# R7FS3A17 register map
Vendor: Renesas; Series: S3; File version: 1.2
CPU: CM4 r0p1, little endian, MPU, FPU, VTOR, 4 interrupt priority bits
Registers are 8-bit, read-write, reset 0x0 unless marked. A register's access mark holds for its fields unless they carry their own. Offsets are from the block's base; [hi:lo] are bit positions; {n}, {i} and the like mark numbered series; 'fields as' and 'values as' point back to an identical list; <NAME> marks a mode.

## SYSTEM — System Control
Base 0x4001E000
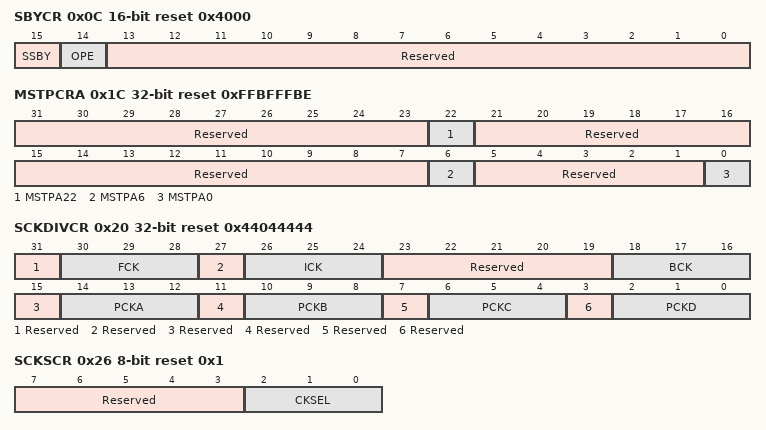
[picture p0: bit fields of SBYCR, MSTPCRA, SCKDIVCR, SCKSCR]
0x0C SBYCR 16-bit reset 0x4000 — Standby Control Register
  [15] SSBY — Software Standby
    0=Sleep mode; 1=Software Standby mode
  [14] OPE — Output Port Enable
    0=In software standby mode Address output pins, Data output pins, and other bus control signal output pins are set to the high-impedance state. In snooze mode, the status of the address bus and bus control signals are same as before entering software standby mode.; 1=In software standby mode Address output pins, Data output pins, and other bus control signal output pins retain the output state
  [13:0] Reserved — These bits are read as 00000000000000. The write value should be 00000000000000.
0x1C MSTPCRA 32-bit reset 0xFFBFFFBE — Module Stop Control Register A
  [31:23] Reserved — These bits are read as 111111111. The write value should be 111111111.
  [22] MSTPA22 — DMA Controller/Data Transfer Controller Module Stop
    0=Cancel the module-stop state; 1=Enter the module-stop state
  [21:7] Reserved — These bits are read as 111111111111111. The write value should be 111111111111111.
  [6] MSTPA6 — ECCRAM Module Stop
    values as MSTPA22
  [5:1] Reserved — These bits are read as 11111. The write value should be 11111.
  [0] MSTPA0 — RAM0 Module Stop
    values as MSTPA22
0x20 SCKDIVCR 32-bit reset 0x44044444 — System Clock Division Control Register
  [31] Reserved — This bit is read as 0. The write value should be 0.
  [30:28] FCK — Flash IF Clock (FCLK) Select
    0=/1; 1=/2; 2=/4; 3=/8; 4=/16; 5=/32; 6=/64; other=others (Setting prohibited)
  [27] Reserved — This bit is read as 0. The write value should be 0.
  [26:24] ICK — System Clock (ICLK) Select
    values as FCK
  [23:19] Reserved — These bits are read as 00000. The write value should be 00000.
  [18:16] BCK — External Bus Clock (BCLK) Select
    values as FCK
  [15] Reserved — This bit is read as 0. The write value should be 0.
  [14:12] PCKA — Peripheral Module Clock A (PCLKA) Select
    values as FCK
  [11] Reserved — This bit is read as 0. The write value should be 0.
  [10:8] PCKB — Peripheral Module Clock B (PCLKB) Select
    values as FCK
  [7] Reserved — This bit is read as 0. The write value should be 0.
  [6:4] PCKC — Peripheral Module Clock C (PCLKC) Select
    values as FCK
  [3] Reserved — This bit is read as 0. The write value should be 0.
  [2:0] PCKD — Peripheral Module Clock D (PCLKD) Select
    values as FCK
0x26 SCKSCR reset 0x1 — System Clock Source Control Register
  [7:3] Reserved — These bits are read as 00000. The write value should be 00000.
  [2:0] CKSEL — Clock Source Select Selecting the system clock source faster than 32MHz(system clock source > 32MHz ) is prohibit when SCKDIVCR.ICK[2:0] bits select the division-by-1 and MEMWAIT.MEMWAIT =0.
    0=HOCO; 1=MOCO; 2=LOCO; 3=Main clock oscillator; 4=Sub-clock oscillator; 5=PLL; other=others (Setting prohibited)
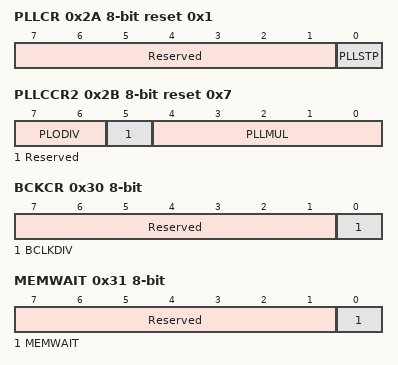
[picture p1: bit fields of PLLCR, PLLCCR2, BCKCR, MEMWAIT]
0x2A PLLCR reset 0x1 — PLL Control Register
  [7:1] Reserved — These bits are read as 0000000. The write value should be 0000000.
  [0] PLLSTP — PLL Stop Control
    0=PLL is operating; 1=PLL is stopped
0x2B PLLCCR2 reset 0x7 — PLL Clock Control Register2
  [7:6] PLODIV — PLL Output Frequency Division Ratio Select
    0=/1; 1=/2; 2=/4; 3=Setting prohibited
  [5] Reserved — This bit is read as 0. The write value should be 0.
  [4:0] PLLMUL — PLL Frequency Multiplication Factor Select
    15=Settings prohibited; other=others (x PLLMUL[4:0] +1)
0x30 BCKCR — External Bus Clock Control Register
  [7:1] Reserved — These bits are read as 0000000. The write value should be 0000000.
  [0] BCLKDIV — EBCLK Pin Output Select
    0=BCLK; 1=BCLK/2
0x31 MEMWAIT — Memory Wait Cycle Control Register
  [7:1] Reserved — These bits are read as 0000000. The write value should be 0000000.
  [0] MEMWAIT — Memory Wait Cycle Select Note: Writing 0 to the MEMWAIT is prohibited when SCKDIVCR.ICK selects division by 1 and SCKSCR.CKSEL[2:0] bits select the system clock source that is faster than 32 MHz (ICLK > 32 MHz).
    0=no wait; 1=wait
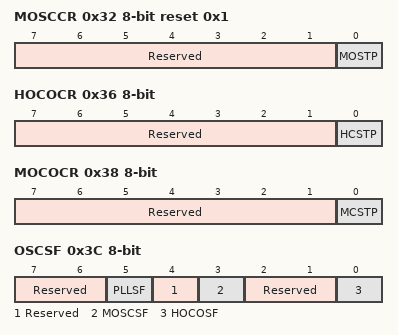
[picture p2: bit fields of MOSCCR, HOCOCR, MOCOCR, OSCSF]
0x32 MOSCCR reset 0x1 — Main Clock Oscillator Control Register
  [7:1] Reserved — These bits are read as 0000000. The write value should be 0000000.
  [0] MOSTP — Main Clock Oscillator Stop Note: MOMCR register must be set before setting MOSTP to 0.
    0=Main clock oscillator is operating; 1=Main clock oscillator is stopped
0x36 HOCOCR (reset mask 0xFE) — High-Speed On-Chip Oscillator Control Register
  [7:1] Reserved — These bits are read as 0000000. The write value should be 0000000.
  [0] HCSTP — HOCO Stop
    0=HOCO is operating; 1=HOCO is stopped
0x38 MOCOCR — Middle-Speed On-Chip Oscillator Control Register
  [7:1] Reserved — These bits are read as 0000000. The write value should be 0000000.
  [0] MCSTP — MOCO Stop
    0=MOCO is operating; 1=MOCO is stopped
0x3C OSCSF ro (reset mask 0xFE) — Oscillation Stabilization Flag Register
  [7:6] Reserved — These bits are read as 00.
  [5] PLLSF — PLL Clock Oscillation Stabilization Flag
    0=The PLL clock is stopped or oscillation of the PLL clock has not yet become stable; 1=Oscillation of the PLL clock is stable so the clock is available for use as the system clock
  [4] Reserved — This bit is read as 0.
  [3] MOSCSF — Main Clock Oscillation Stabilization Flag
    0=MOSTP = 1 (stopping the main clock oscillator) or oscillation of the main clock has not yet become stable; 1=Oscillation of the main clock is stable so the clock is available for use as the system clock
  [2:1] Reserved — These bits are read as 00.
  [0] HOCOSF — HOCO Clock Oscillation Stabilization Flag NOTE: The HOCOSF bit value after a reset is 1 when the OFS1.HOCOEN bit is 0. It is 0 when the OFS1.HOCOEN bit is 1.
    0=The HOCO clock is stopped or oscillation of the HOCO clock has not yet become stable; 1=Oscillation of the HOCO clock is stable so the clock is available for use as the system clock
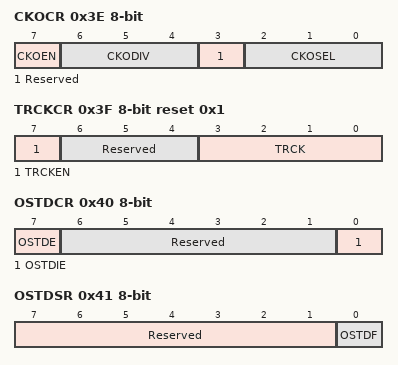
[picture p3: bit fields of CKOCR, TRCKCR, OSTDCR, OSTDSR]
0x3E CKOCR — Clock Out Control Register
  [7] CKOEN — Clock out enable
    0=Clock Out disable; 1=Clock Out enable
  [6:4] CKODIV — Clock out input frequency Division Select
    0=/1; 1=/2; 2=/4; 3=/8; 4=/16; 5=/32; 6=/64; 7=/128
  [3] Reserved — This bit is read as 0. The write value should be 0.
  [2:0] CKOSEL — Clock out source select
    0=HOCO; 1=MOCO; 2=LOCO; 3=MOSC; 4=SOSC; other=others (Setting prohibited)
0x3F TRCKCR reset 0x1 — Trace Clock Control Register
  [7] TRCKEN — Trace Clock operating enable
    0=Operation disabled; 1=Operation enabled
  [6:4] Reserved — These bits are read as 000. The write value should be 000.
  [3:0] TRCK — Trace Clock operating frequency select
    0=/1; 1=/2(value after reset); 2=/4; other=others (Setting prohibited)
0x40 OSTDCR — Oscillation Stop Detection Control Register
  [7] OSTDE — Oscillation Stop Detection Function Enable
    0=Oscillation stop detection function is disabled; 1=Oscillation stop detection function is enabled
  [6:1] Reserved — These bits are read as 000000. The write value should be 000000.
  [0] OSTDIE — Oscillation Stop Detection Interrupt Enable
    0=The oscillation stop detection interrupt is disabled. Oscillation stop detection is not notified to the POEG.; 1=The oscillation stop detection interrupt is enabled. Oscillation stop detection is notified to the POEG.
0x41 OSTDSR — Oscillation Stop Detection Status Register
  [7:1] Reserved — These bits are read as 0000000. The write value should be 0000000.
  [0] OSTDF write-0-clears read-modifies — Oscillation Stop Detection Flag
    0=The main clock oscillation stop has not been detected; 1=The main clock oscillation stop has been detected
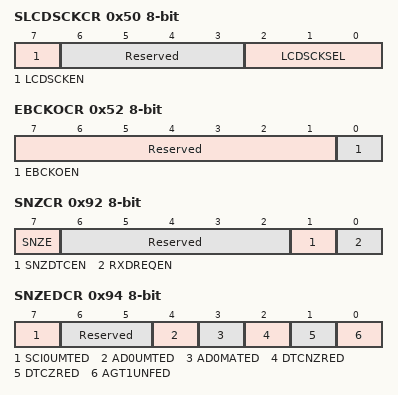
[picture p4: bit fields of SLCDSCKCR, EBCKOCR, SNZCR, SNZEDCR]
0x50 SLCDSCKCR — Segment LCD Source Clock Control Register
  [7] LCDSCKEN — LCD Source Clock Out Enable
    0=LCD source clock out disabled; 1=LCD source clock out enabled
  [6:3] Reserved — These bits are read as 0000. The write value should be 0000.
  [2:0] LCDSCKSEL — LCD Source Clock (LCDSRCCLK) Select
    0=LOCO; 1=SOSC; 2=MOSC; 4=HOCO; other=others (Settings other than above are prohibited.)
0x52 EBCKOCR — External Bus Clock Output Control Register
  [7:1] Reserved — These bits are read as 0000000. The write value should be 0000000.
  [0] EBCKOEN — EBCLK Pin Output Control
    0=BCLK pin output is disabled. (Fixed high); 1=BCLK pin output is enabled
0x61 MOCOUTCR — MOCO User Trimming Control Register
  [7:0] MOCOUTRM — MOCO User Trimming 1000_0000 : -128 1000_0001 : -127 1000_0010 : -126 . . . 1111_1111 : -1 0000_0000 : Center Code 0000_0001 : +1 . . . 0111_1101 : +125 0111_1110 : +126 0111_1111 : +127 These bits are added to original MOCO trimming bits
0x62 HOCOUTCR — HOCO User Trimming Control Register
  [7:0] HOCOUTRM — HOCO User Trimming 1000_0000 : -128 1000_0001 : -127 1000_0010 : -126 . . . 1111_1111 : -1 0000_0000 : Center Code 0000_0001 : +1 . . . 0111_1101 : +125 0111_1110 : +126 0111_1111 : +127 These bits are added to original HOCO trimming bits
0x92 SNZCR — Snooze Control Register
  [7] SNZE — Snooze Mode Enable
    0=Disable Snooze Mode; 1=Enable Snooze Mode
  [6:2] Reserved — These bits are read as 00000. The write value should be 00000.
  [1] SNZDTCEN — DTC Enable in Snooze Mode
    0=Disable DTC operation; 1=Enable DTC operation
  [0] RXDREQEN — RXD0 Snooze Request Enable NOTE: Do not set to 1 other than in asynchronous mode.
    0=Ignore RXD0 falling edge in Software Standby mode; 1=Accept RXD0 falling edge in Standby mode as a request to transit to Snooze mode
0x94 SNZEDCR — Snooze End Control Register
  [7] SCI0UMTED — SCI0 Address Mismatch Snooze End Enable
    0=Disable the Snooze End request; 1=Enable the Snooze End request
  [6:5] Reserved — These bits are read as 00. The write value should be 00.
  [4] AD0UMTED — ADC140 Compare Mismatch Snooze End Enable
    values as SCI0UMTED
  [3] AD0MATED — ADC140 Compare Match Snooze End Enable
    values as SCI0UMTED
  [2] DTCNZRED — Not Last DTC Transmission Completion Snooze End Enable
    values as SCI0UMTED
  [1] DTCZRED — Last DTC Transmission Completion Snooze End Enable
    values as SCI0UMTED
  [0] AGT1UNFED — AGT1 Underflow Snooze End Enable
    values as SCI0UMTED
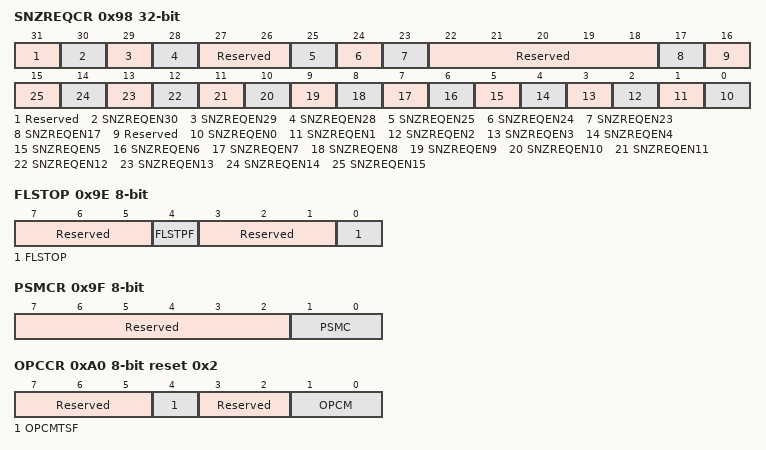
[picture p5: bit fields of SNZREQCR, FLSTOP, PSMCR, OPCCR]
0x98 SNZREQCR 32-bit — Snooze Request Control Register
  [31] Reserved — This bit is read as 0. The write value should be 0.
  [30] SNZREQEN30 — Snooze Request Enable 30 Enable AGT1 compare match B snooze request
    0=Disable snooze request; 1=Enable snooze request
  [29] SNZREQEN29 — Snooze Request Enable 29 Enable AGT1 compare match A snooze request
    0=Disable snooze request; 1=Enable snooze request
  [28] SNZREQEN28 — Snooze Request Enable 28 Enable AGT1 underflow snooze request
    0=Disable snooze request; 1=Enable snooze request
  [27:26] Reserved — These bits are read as 00. The write value should be 00.
  [25] SNZREQEN25 — Snooze Request Enable 25 Enable RTC period snooze request
    0=Disable snooze request; 1=Enable snooze request
  [24] SNZREQEN24 — Snooze Request Enable 24 Enable RTC alarm snooze request
    0=Disable snooze request; 1=Enable snooze request
  [23] SNZREQEN23 — Snooze Request Enable 23 Enable RTC alarm snooze request
    0=Disable snooze request; 1=Enable snooze request
  [22:18] Reserved — These bits are read as 00000. The write value should be 00000.
  [17] SNZREQEN17 — Snooze Request Enable 17 Enable KINT snooze request
    0=Disable snooze request; 1=Enable snooze request
  [16] Reserved — This bit is read as 0. The write value should be 0.
  [n] SNZREQEN{n} (n=0..15) — Snooze Request Enable {n} Enable IRQ{n} pin snooze request
    0=Disable snooze request; 1=Enable snooze request
0x9E FLSTOP — Flash Operation Control Register
  [7:5] Reserved — These bits are read as 000. The write value should be 000.
  [4] FLSTPF — Flash Memory Operation Status Flag
    0=Transition completed; 1=During transition (from the flash-stop-status to flash-operating-status or vice versa)
  [3:1] Reserved — These bits are read as 000. The write value should be 000.
  [0] FLSTOP — Selecting ON/OFF of the Flash Memory Operation
    0=Code flash and data flash memory operates; 1=Code flash and data flash memory stops
0x9F PSMCR — Power Save Memory Control Register
  [7:2] Reserved — These bits are read as 000000. The write value should be 000000.
  [1:0] PSMC — Power save memory control.
    0=All RAM is on Software Standby mode; 1=48KB RAM is on in Software Standby mode; other=others (Setting prohibited.)
0xA0 OPCCR reset 0x2 — Operating Power Control Register
  [7:5] Reserved — These bits are read as 000. The write value should be 000.
  [4] OPCMTSF — Operating Power Control Mode Transition Status Flag
    0=Transition completed; 1=During transition
  [3:2] Reserved — These bits are read as 00. The write value should be 00.
  [1:0] OPCM — Operating Power Control Mode Select
    0=High-speed mode; 1=Middle-speed mode; 2=Low-voltage mode; 3=Low-speed mode
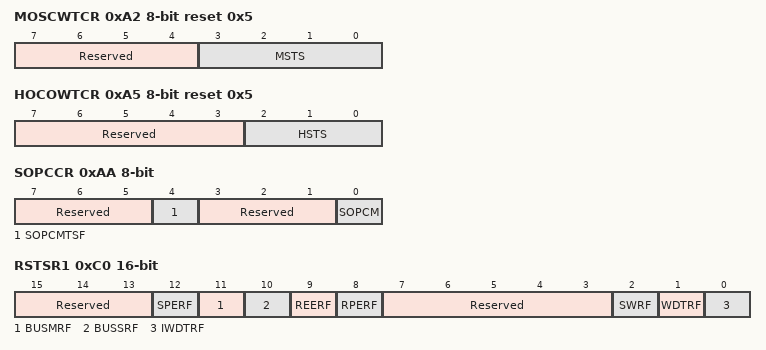
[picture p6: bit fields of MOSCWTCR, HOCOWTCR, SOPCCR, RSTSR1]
0xA2 MOSCWTCR reset 0x5 — Main Clock Oscillator Wait Control Register
  [7:4] Reserved — These bits are read as 0000. The write value should be 0000.
  [3:0] MSTS — Main clock oscillator wait time setting
    0=Wait time = 2 cycles (0.25 us); 1=Wait time = 1024 cycles (128 us); 2=Wait time = 2048 cycles (256 us); 3=Wait time = 4096 cycles (512 us); 4=Wait time = 8192 cycles (1024 us); 5=Wait time = 16384 cycles (2048 us) (value after reset); 6=Wait time = 32768 cycles (4096 us); 7=Wait time = 65536 cycles (8192 us); 8=Wait time = 131072 cycles (16384 us); 9=Wait time = 262144 cycles (32768 us); other=others (Setting prohibited)
0xA5 HOCOWTCR reset 0x5 — High-Speed On-Chip Oscillator Wait Control Register
  [7:3] Reserved — These bits are read as 00000. The write value should be 00000.
  [2:0] HSTS — HOCO wait time setting
    5=If HOCO frequency is other than 64MHz, should set the value to 101b; 6=If HOCO frequency = 64MHz, should set the value to 110b; other=others (Setting prohibited)
0xAA SOPCCR — Sub Operating Power Control Register
  [7:5] Reserved — These bits are read as 000. The write value should be 000.
  [4] SOPCMTSF ro — Sub Operating Power Control Mode Transition Status Flag
    0=Transition completed; 1=During transition
  [3:1] Reserved — These bits are read as 000. The write value should be 000.
  [0] SOPCM — Sub Operating Power Control Mode Select
    0=Other than Subosc-speed mode; 1=Subosc-speed mode
0xC0 RSTSR1 16-bit (reset mask 0xE0F8) — Reset Status Register 1
  [15:13] Reserved — These bits are read as 000. The write value should be 000.
  [12] SPERF write-0-clears read-modifies — SP Error Reset Detect Flag Note: Only 0 can be written to clear the flag. The reset flag must be written as 0 after the reset flag is read as 1.
    0=SP error reset not detected; 1=SP error reset detected
  [11] BUSMRF write-0-clears read-modifies — Bus Master MPU Reset Detect Flag Note: Only 0 can be written to clear the flag. The reset flag must be written as 0 after the reset flag is read as 1.
    0=Bus Master MPU reset not detected; 1=Bus Master MPU reset detected
  [10] BUSSRF write-0-clears read-modifies — Bus Slave MPU Reset Detect Flag Note: Only 0 can be written to clear the flag. The reset flag must be written as 0 after the reset flag is read as 1.
    0=Bus Slave MPU reset not detected; 1=Bus Slave MPU reset detected
  [9] REERF write-0-clears read-modifies — RAM ECC Error Reset Detect Flag Note: Only 0 can be written to clear the flag. The reset flag must be written as 0 after the reset flag is read as 1.
    0=RAM ECC error reset not detected; 1=RAM ECC error reset detected
  [8] RPERF write-0-clears read-modifies — RAM Parity Error Reset Detect Flag Note: Only 0 can be written to clear the flag. The reset flag must be written as 0 after the reset flag is read as 1.
    0=RAM parity error reset not detected; 1=RAM parity error reset detected
  [7:3] Reserved — These bits are read as 00000. The write value should be 00000.
  [2] SWRF write-0-clears read-modifies — Software Reset Detect Flag Note: Only 0 can be written to clear the flag. The reset flag must be written as 0 after the reset flag is read as 1.
    0=Software reset not detected; 1=Software reset detected
  [1] WDTRF write-0-clears read-modifies — Watchdog Timer Reset Detect Flag Note: Only 0 can be written to clear the flag. The reset flag must be written as 0 after the reset flag is read as 1.
    0=Watchdog timer reset not detected; 1=Watchdog timer reset detected
  [0] IWDTRF write-0-clears read-modifies — Independent Watchdog Timer Reset Detect Flag Note: Only 0 can be written to clear the flag. The reset flag must be written as 0 after the reset flag is read as 1.
    0=Independent watchdog timer reset not detected; 1=Independent watchdog timer reset detected
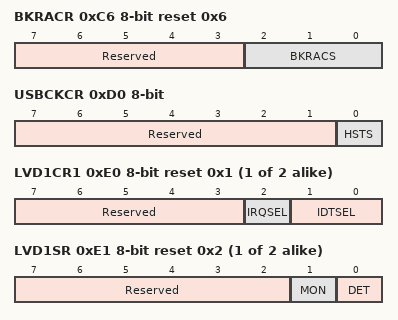
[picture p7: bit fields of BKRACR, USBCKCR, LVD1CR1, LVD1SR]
0xC6 BKRACR reset 0x6 — Backup Register Access Control Register
  [7:3] Reserved — These bits are read as 00000. The write value should be 00000.
  [2:0] BKRACS — Backup Register Access Control Register
    0=Access control disable. When System clock source is SOSC or LOCO.; 6=Access control enable. System clock source is other than SOSC or LOCO.; other=others (Setting prohibited)
0xD0 USBCKCR — USB Clock Control register
  [7:1] Reserved — These bits are read as 0000000. The write value should be 0000000.
  [0] HSTS — USB Clock Source Select
    0=PLL(Value after reset); 1=HOCO
{0xDE+2i} LVD{i}CR1 (i=1..2) reset 0x1 — Voltage Monitor {i} Circuit Control Register 1
  [7:3] Reserved — These bits are read as 00000. The write value should be 00000.
  [2] IRQSEL — Voltage Monitor Interrupt Type Select
    0=Non-maskable interrupt; 1=Maskable interrupt
  [1:0] IDTSEL — Voltage Monitor Interrupt Generation Condition Select
    0=When VCC>=Vdet (rise) is detected; 1=When VCC<Vdet (drop) is detected; 2=When drop and rise are detected; 3=Settings prohibited
{0xDF+2i} LVD{i}SR (i=1..2) reset 0x2 — Voltage Monitor {i} Circuit Status Register
  [7:2] Reserved — These bits are read as 000000. The write value should be 000000.
  [1] MON ro — Voltage Monitor Signal Monitor Flag
    0=VCC < Vdet; 1=VCC >= Vdet or MON bit is disabled
  [0] DET write-0-clears read-modifies — Voltage Monitor Voltage Change Detection Flag NOTE: Only 0 can be written to this bit. After writing 0 to this bit, it takes 2 system clock cycles for the bit to be read as 0.
    0=Not detected; 1=Vdet1 passage detection
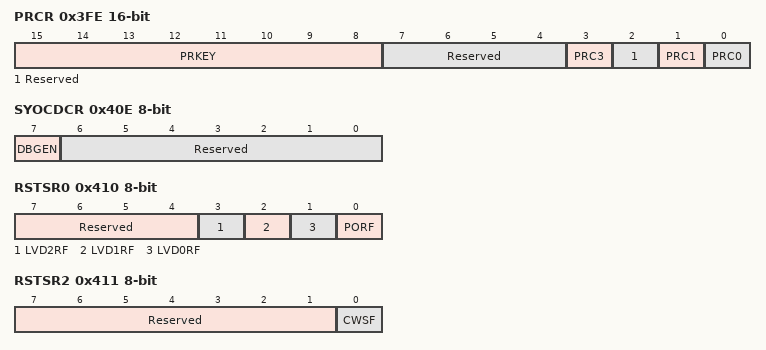
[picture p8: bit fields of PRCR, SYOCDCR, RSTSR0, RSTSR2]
0x3FE PRCR 16-bit — Protect Register
  [15:8] PRKEY wo — PRC Key Code
    90=Enables writing to the PRCR register; other=others (Disables writing to the PRCR register.)
  [7:4] Reserved — These bits are read as 0000. The write value should be 0000.
  [3] PRC3 — Protect Bit 3
    0=Writes protected; 1=Writes not protected
  [2] Reserved — This bit is read as 0. The write value should be 0.
  [1] PRC1 — Protect Bit 1
    0=Writes protected; 1=Writes not protected
  [0] PRC0 — Protect Bit 0
    0=Writes protected; 1=Writes not protected
0x40E SYOCDCR — System Control OCD Control Register
  [7] DBGEN — Debugger Enable bit
    0=On-chip debugger is disabled; 1=On-chip debugger is enabled
  [6:0] Reserved — These bits are read as 0000000. The write value should be 0000000.
0x410 RSTSR0 (reset mask 0xF0) — Reset Status Register 0
  [7:4] Reserved — These bits are read as 0000. The write value should be 0000.
  [3] LVD2RF write-0-clears read-modifies — Voltage Monitor 2 Reset Detect Flag Note: Only 0 can be written to clear the flag. The reset flag must be written with 0 after the reset flag is read as 1.
    0=Voltage Monitor 2 reset not detected; 1=Voltage Monitor 2 reset detected
  [2] LVD1RF write-0-clears read-modifies — Voltage Monitor 1 Reset Detect Flag Note: Only 0 can be written to clear the flag. The reset flag must be written with 0 after the reset flag is read as 1.
    0=Voltage Monitor 1 reset not detected; 1=Voltage Monitor 1 reset detected
  [1] LVD0RF write-0-clears read-modifies — Voltage Monitor 0 Reset Detect Flag Note: Only 0 can be written to clear the flag. The reset flag must be written with 0 after the reset flag is read as 1.
    0=Voltage Monitor 0 reset not detected; 1=Voltage Monitor 0 reset detected
  [0] PORF write-0-clears read-modifies — Power-On Reset Detect Flag Note: Only 0 can be written to clear the flag. The reset flag must be written with 0 after the reset flag is read as 1.
    0=Power-on reset not detected; 1=Power-on reset detected
0x411 RSTSR2 (reset mask 0xFE) — Reset Status Register 2
  [7:1] Reserved — These bits are read as 0000000. The write value should be 0000000.
  [0] CWSF write-1-sets read-modifies — Cold/Warm Start Determination Flag Note: Only 1 can be written to set the flag.
    0=Cold start; 1=Warm start
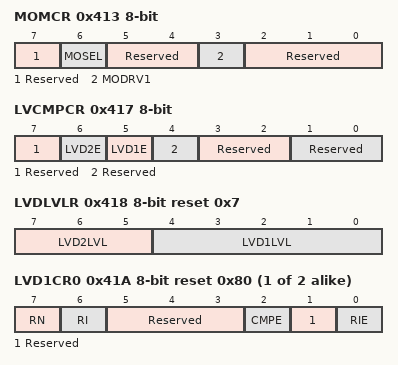
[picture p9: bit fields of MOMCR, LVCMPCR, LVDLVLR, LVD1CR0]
0x413 MOMCR — Main Clock Oscillator Mode Oscillation Control Register
  [7] Reserved — This bit is read as 0. The write value should be 0.
  [6] MOSEL — Main Clock Oscillator Switching
    0=Resonator; 1=External clock input
  [5:4] Reserved — These bits are read as 00. The write value should be 00.
  [3] MODRV1 — Main Clock Oscillator Drive Capability 1 Switching
    0=10 MHz to 20 MHz; 1=1 MHz to 10 MHz
  [2:0] Reserved — These bits are read as 000. The write value should be 000.
0x417 LVCMPCR — Voltage Monitor Circuit Control Register
  [7] Reserved — This bit is read as 0. The write value should be 0.
  [6] LVD2E — Voltage Detection 2 Enable
    0=Voltage detection 2 circuit disabled; 1=Voltage detection 2 circuit enabled
  [5] LVD1E — Voltage Detection 1 Enable
    0=Voltage detection 1 circuit disabled; 1=Voltage detection 1 circuit enabled
  [4] Reserved — This bit is read as 0. The write value should be 0.
  [3:2] Reserved — These bits are read as 00. The write value should be 00.
  [1:0] Reserved — These bits are read as 00. The write value should be 00.
0x418 LVDLVLR reset 0x7 — Voltage Detection Level Select Register
  [7:5] LVD2LVL — Voltage Detection 2 Level Select (Standard voltage during drop in voltage)
    0=4.29V (Vdet2_0); 1=4.14V (Vdet2_1); 2=4.02V (Vdet2_2); 3=3.84V (Vdet2_3); other=others (Setting prohibited.)
  [4:0] LVD1LVL — Voltage Detection 1 Level Select (Standard voltage during drop in voltage)
    0=4.29V (Vdet1_0); 1=4.14V (Vdet1_1); 2=4.02V (Vdet1_2); 3=3.84V (Vdet1_3); 4=3.10V (Vdet1_4); 5=3.00V (Vdet1_5); 6=2.90V (Vdet1_6); 7=2.79V (Vdet1_7); 8=2.68V (Vdet1_8); 9=2.58V (Vdet1_9); 10=2.48V (Vdet1_A); 11=2.20V (Vdet1_B); 12=1.96V (Vdet1_C); 13=1.86V (Vdet1_D); 14=1.75V (Vdet1_E); 15=1.65V (Vdet1_F); other=others (Setting prohibited)
{0x419+i} LVD{i}CR0 (i=1..2) reset 0x80 (reset mask 0xF7) — Voltage Monitor {i} Circuit Control Register 0
  [7] RN — Voltage Monitor Reset Negate Select
    0=Negation follows a stabilization time (tLVD) after VCC > Vdet1 is detected; 1=Negation follows a stabilization time (tLVD) after assertion of the LVD reset
  [6] RI — Voltage Monitor Circuit Mode Select
    0=Voltage Monitor interrupt during Vdet1 passage; 1=Voltage Monitor reset enabled when the voltage falls to and below Vdet1
  [5:3] Reserved — These bits are read as 000. The write value should be 000.
  [2] CMPE — Voltage Monitor Circuit Comparison Result Output Enable
    0=Voltage Monitor circuit comparison result output disabled; 1=Voltage Monitor circuit comparison result output enabled
  [1] Reserved — This bit is read as 0. The write value should be 0.
  [0] RIE — Voltage Monitor Interrupt/Reset Enable
    0=Disabled; 1=Enabled
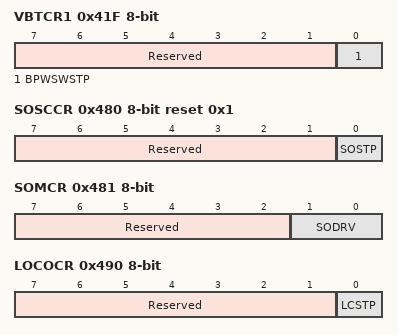
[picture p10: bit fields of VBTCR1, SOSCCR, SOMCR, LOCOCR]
0x41F VBTCR1 — VBATT Control Register1
  [7:1] Reserved — These bits are read as 0000000. The write value should be 0000000.
  [0] BPWSWSTP — Battery Power supply Switch Stop
    0=Battery Power supply Switch Enable; 1=Battery Power supply Switch stop
0x480 SOSCCR reset 0x1 — Sub-Clock Oscillator Control Register
  [7:1] Reserved — These bits are read as 0000000. The write value should be 0000000.
  [0] SOSTP — Sub-Clock Oscillator Stop
    0=Sub-clock oscillator is operating; 1=Sub-clock oscillator is stopped
0x481 SOMCR — Sub Clock Oscillator Mode Control Register
  [7:2] Reserved — These bits are read as 000000. The write value should be 000000.
  [1:0] SODRV — Sub-Clock Oscillator Drive Capability Switching
    0=Normal mode; 1=Low power mode 1; 2=Low power mode 2; 3=Low power mode 3
0x490 LOCOCR — Low-Speed On-Chip Oscillator Control Register
  [7:1] Reserved — These bits are read as 0000000. The write value should be 0000000.
  [0] LCSTP — LOCO Stop
    0=LOCO is operating; 1=LOCO is stopped
0x492 LOCOUTCR — LOCO User Trimming Control Register
  [7:0] LOCOUTRM — LOCO User Trimming 1000_0000 : -128 1000_0001 : -127 1000_0010 : -126 . . . 1111_1111 : -1 0000_0000 : Center Code 0000_0001 : +1 . . . 0111_1101 : +125 0111_1110 : +126 0111_1111 : +127 These bits are added to original LOCO trimming bits
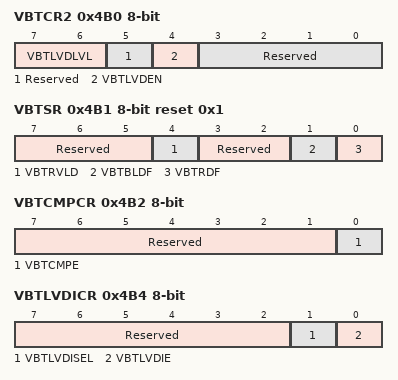
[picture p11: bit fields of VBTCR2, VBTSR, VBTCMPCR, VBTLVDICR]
0x4B0 VBTCR2 — VBATT Control Register2
  [7:6] VBTLVDLVL — VBATT Pin Voltage Low Voltage Detect Level Select Bit
    0=2.7V; 1=Setting prohibited; 2=2.3V; 3=2.1V
  [5] Reserved — This bit is read as 0. The write value should be 0.
  [4] VBTLVDEN — VBATT Pin Low Voltage Detect Enable Bit
    0=VBATT pin low voltage detect disable; 1=VBATT pin low voltage detect enable
  [3:0] Reserved — These bits are read as 0000. The write value should be 0000.
0x4B1 VBTSR reset 0x1 (reset mask 0xEC) — VBATT Status Register
  [7:5] Reserved — These bits are read as 000. The write value should be 000.
  [4] VBTRVLD ro — VBATT_R Valid
    0=VBATT_R area not valid; 1=VBATT_R area valid
  [3:2] Reserved — These bits are read as 00. The write value should be 00.
  [1] VBTBLDF write-0-clears read-modifies — VBATT Battery Low voltage Detect Flag
    0=VBATT pin low voltage not detected; 1=VBATT pin low voltage detected
  [0] VBTRDF write-0-clears read-modifies — VBAT_R Reset Detect Flag
    0=VBATT_R voltage power-on reset not detected; 1=VBATT_R selected voltage power-on reset detected
0x4B2 VBTCMPCR — VBATT Comparator Control Register
  [7:1] Reserved — These bits are read as 0000000. The write value should be 0000000.
  [0] VBTCMPE — VBATT pin low voltage detect circuit output enable
    0=VBATT pin low voltage detect circuit output disabled; 1=VBATT pin low voltage detect circuit output enabled
0x4B4 VBTLVDICR — VBATT Pin Low Voltage Detect Interrupt Control Register
  [7:2] Reserved — These bits are read as 000000. The write value should be 000000.
  [1] VBTLVDISEL — Pin Low Voltage Detect Interrupt Select bit
    0=Non Maskable Interrupt; 1=Maskable Interrupt
  [0] VBTLVDIE — VBATT Pin Low Voltage Detect Interrupt Enable bit
    0=VBATT Pin Low Voltage Detect Interrupt Disable; 1=VBATT Pin Low Voltage Detect Interrupt Enable
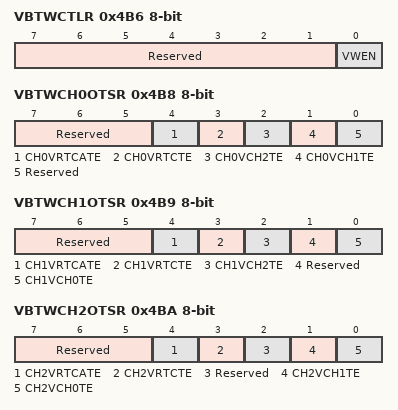
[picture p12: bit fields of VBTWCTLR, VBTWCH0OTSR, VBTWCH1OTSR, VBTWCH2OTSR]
0x4B6 VBTWCTLR — VBATT Wakeup function Control Register
  [7:1] Reserved — These bits are read as 0000000. The write value should be 0000000.
  [0] VWEN — VBATT wakeup enable
    0=Disable Wakeup function; 1=Enable Wakeup function
0x4B8 VBTWCH0OTSR — VBATT Wakeup I/O 0 Output Trigger Select Register
  [7:5] Reserved — These bits are read as 000. The write value should be 000.
  [4] CH0VRTCATE — VBATWIO0 Output RTC Alarm Signal Enable
    0=VBATT wakeup I/O 0 output trigger by the RTC alarm signal is disabled; 1=VBATT wakeup I/O 0 output trigger by the RTC alarm signal is enabled
  [3] CH0VRTCTE — VBATWIO0 Output RTC Periodic Signal Enable
    0=VBATT wakeup I/O 0 output trigger by the RTC periodic signal is disabled; 1=VBATT wakeup I/O 0 output trigger by the RTC periodic signal is enabled
  [2] CH0VCH2TE — VBATWIO0 Output VBATWIO2 Trigger Enable
    0=VBATT wakeup I/O 0 output trigger by the VBATWIO2 pin is disabled; 1=VBATT wakeup I/O 0 output trigger by the VBATWIO2 pin is enabled
  [1] CH0VCH1TE — VBATWIO0 Output VBATWIO1 Trigger Enable
    0=VBATT wakeup I/O 0 output trigger by the VBATWIO1 pin is disabled; 1=VBATT wakeup I/O 0 output trigger by the VBATWIO1 pin is enabled
  [0] Reserved — This bit is read as 0. The write value should be 0.
0x4B9 VBTWCH1OTSR — VBATT Wakeup I/O 1 Output Trigger Select Register
  [7:5] Reserved — These bits are read as 000. The write value should be 000.
  [4] CH1VRTCATE — VBATWIO1 Output RTC Alarm Signal Enable
    0=VBATT wakeup I/O 1 output trigger by the RTC alarm signal is disabled; 1=VBATT wakeup I/O 1 output trigger by the RTC alarm signal is enabled
  [3] CH1VRTCTE — VBATWIO1 Output RTC Periodic Signal Enable
    0=VBATT wakeup I/O 1 output trigger by the RTC periodic signal is disabled; 1=VBATT wakeup I/O 1 output trigger by the RTC periodic signal is enabled
  [2] CH1VCH2TE — VBATWIO1 Output VBATWIO2 Trigger Enable
    0=VBATT wakeup I/O 1 output trigger by the VBATWIO2 pin is disabled; 1=VBATT wakeup I/O 1 output trigger by the VBATWIO2 pin is enabled
  [1] Reserved — This bit is read as 0. The write value should be 0.
  [0] CH1VCH0TE — VBATWIO1 Output VBATWIO0 Trigger Enable
    0=VBATT wakeup I/O 1 output trigger by the VBATWIO0 pin is disabled; 1=VBATT wakeup I/O 1 output trigger by the VBATWIO0 pin is enabled
0x4BA VBTWCH2OTSR — VBATT Wakeup I/O 2 Output Trigger Select Register
  [7:5] Reserved — These bits are read as 000. The write value should be 000.
  [4] CH2VRTCATE — VBATWIO2 Output RTC Alarm Signal Enable
    0=VBATT wakeup I/O 2 output trigger by the RTC alarm signal is disabled; 1=VBATT wakeup I/O 2 output trigger by the RTC alarm signal is enabled
  [3] CH2VRTCTE — VBATWIO2 Output RTC Periodic Signal Enable
    0=VBATT wakeup I/O 2 output trigger by the RTC periodic signal is disabled; 1=VBATT wakeup I/O 2 output trigger by the RTC periodic signal is enabled
  [2] Reserved — This bit is read as 0. The write value should be 0.
  [1] CH2VCH1TE — VBATWIO2 Output VBATWIO1 Trigger Enable
    0=VBATT wakeup I/O 2 output trigger by the VBATWIO1 pin is disabled; 1=VBATT wakeup I/O 2 output trigger by the VBATWIO1 pin is enabled
  [0] CH2VCH0TE — VBATWIO2 Output VBATWIO0 Trigger Enable
    0=VBATT wakeup I/O 2 output trigger by the VBATWIO0 pin is disabled; 1=VBATT wakeup I/O 2 output trigger by the VBATWIO0 pin is enabled
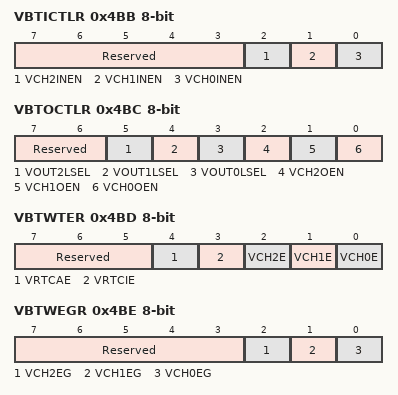
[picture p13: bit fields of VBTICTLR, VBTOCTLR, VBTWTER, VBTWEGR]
0x4BB VBTICTLR — VBATT Input Control Register
  [7:3] Reserved — These bits are read as 00000. The write value should be 00000.
  [2] VCH2INEN — VBATT Wakeup I/O 2 Input Enable
    0=VBATWIO2 and RTCIC2 inputs disabled; 1=VBATWIO2 and RTCIC2 inputs enabled
  [1] VCH1INEN — VBATT Wakeup I/O 1 Input Enable
    0=VBATWIO1, RTCIC1 inputs disabled; 1=VBATWIO1, RTCIC1 inputs enabled
  [0] VCH0INEN — VBATT Wakeup I/O 0 Input Enable
    0=VBATWIO0, RTCIC0 inputs disabled; 1=VBATWIO0, RTCIC0 inputs enabled
0x4BC VBTOCTLR — VBATT Output Control Register
  [7:6] Reserved — These bits are read as 00. The write value should be 00.
  [5] VOUT2LSEL — VBATT Wakeup I/O 2 Output Level Selection
    0=Output L before VBATT wake up trigger; 1=Output H before VBATT wake up trigger
  [4] VOUT1LSEL — VBATT Wakeup I/O 1 Output Level Selection
    values as VOUT2LSEL
  [3] VOUT0LSEL — VBATT Wakeup I/O 0 Output Level Selection
    0=Output L before VBATT wakeup trigger; 1=Output H before VBATT wakeup trigger
  [2] VCH2OEN — VBATT Wakeup I/O 2 Output Enable
    0=VBATWIO2 output disabled; 1=VBATWIO2 output enabled
  [1] VCH1OEN — VBATT Wakeup I/O 1 Output Enable
    0=VBATWIO1 output disabled; 1=VBATWIO1 output enabled
  [0] VCH0OEN — VBATT Wakeup I/O 0 Output Enable
    0=VBATWIO0 output disabled; 1=VBATWIO0 output enabled
0x4BD VBTWTER — VBATT Wakeup Trigger source Enable Register
  [7:5] Reserved — These bits are read as 000. The write value should be 000.
  [4] VRTCAE — RTC Alarm Signal Enable
    0=VBATT wakeup triggered by RTC alarm signal is disabled; 1=VBATT wakeup triggered by RTC alarm signal is enabled
  [3] VRTCIE — RTC Periodic Signal Enable
    0=VBATT wakeup triggered by RTC periodic signal is disabled; 1=VBATT wakeup triggered by RTC periodic signal is enabled
  [2] VCH2E — VBATWIO2 Pin Enable
    0=VBATT wakeup triggered by the VBATWIO2 pin is disabled; 1=VBATT wakeup triggered by the VBATWIO2 pin is enabled
  [1] VCH1E — VBATWIO1 Pin Enable
    0=VBATT wakeup triggered by the VBATWIO1 pin is disabled; 1=VBATT wakeup triggered by the VBATWIO1 pin is enabled
  [0] VCH0E — VBATWIO0 Pin Enable
    0=VBATT wakeup triggered by the VBATWIO0 pin is disabled; 1=VBATT wakeup triggered by the VBATWIO0 pin is enabled
0x4BE VBTWEGR — VBATT Wakeup Trigger source Edge Register
  [7:3] Reserved — These bits are read as 00000. The write value should be 00000.
  [2] VCH2EG — VBATWIO2 Wakeup Trigger Source Edge Select
    0=Wakeup trigger is generated at a falling edge; 1=Wakeup trigger is generated at a rising edge
  [1] VCH1EG — VBATWIO1 Wakeup Trigger Source Edge Select
    values as VCH2EG
  [0] VCH0EG — VBATWIO0 Wakeup Trigger Source Edge Select
    values as VCH2EG
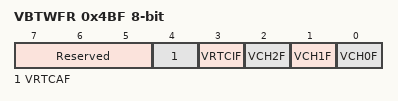
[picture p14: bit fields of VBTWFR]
0x4BF VBTWFR — VBATT Wakeup trigger source Flag Register
  [7:5] Reserved — These bits are read as 000. The write value should be 000.
  [4] VRTCAF write-0-clears read-modifies — VBATT RTC-Alarm Wakeup Trigger Flag
    0=No wakeup trigger by the RTC alarm is generated; 1=A wakeup trigger by the RTC alarm is generated
  [3] VRTCIF write-0-clears read-modifies — VBATT RTC-Interval Wakeup Trigger Flag
    0=No wakeup trigger by the RTC interval is generated; 1=A wakeup trigger by the RTC interval is generated
  [2] VCH2F write-0-clears read-modifies — VBATWIO2 Wakeup Trigger Flag
    0=No wakeup trigger by the VBATWIO2 pin is generated; 1=A wakeup trigger by the VBATWIO2 pin is generated
  [1] VCH1F write-0-clears read-modifies — VBATWIO1 Wakeup Trigger Flag
    0=No wakeup trigger by the VBATWIO1 pin is generated; 1=A wakeup trigger by the VBATWIO1 pin is generated
  [0] VCH0F write-0-clears read-modifies — VBATWIO0 Wakeup Trigger Flag
    0=No wakeup trigger by the VBATWIO0 pin is generated; 1=A wakeup trigger by the VBATWIO0 pin is generated
{0x500+i} VBTBKR[{i}] (i=0..511) reset not defined — VBATT Backup Register [{i}]
  [7:0] VBTBKR — VBTBKR is a 512-byte readable/writable register to store data powered by VBATT. The value of this register is retained even when VCC is not powered but VBATT is powered. VBTBKR is initialized by VBATT selected voltage power-on-reset.
